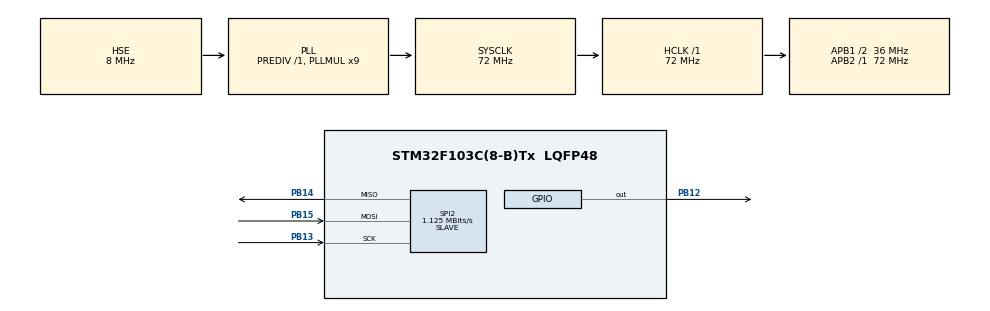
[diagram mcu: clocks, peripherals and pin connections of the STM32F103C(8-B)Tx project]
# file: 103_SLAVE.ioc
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Mcu.Family=STM32F1
Mcu.Name=STM32F103C(8-B)Tx
Mcu.Package=LQFP48
NVIC.PriorityGroup=NVIC_PRIORITYGROUP_4
NVIC.TIM4_IRQn=true\:15\:0\:false\:false\:true\:false\:true
NVIC.TimeBase=TIM4_IRQn
NVIC.TimeBaseIP=TIM4
PA13.Mode=Trace_Asynchronous_SW
PA13.Signal=SYS_JTMS-SWDIO
PA14.Mode=Trace_Asynchronous_SW
PA14.Signal=SYS_JTCK-SWCLK
PB12.GPIO_Speed=GPIO_SPEED_FREQ_HIGH
PB12.PinState=GPIO_PIN_SET
PB12.Signal=GPIO_Output
PB13.Mode=Full_Duplex_Slave
PB13.Signal=SPI2_SCK
PB14.Mode=Full_Duplex_Slave
PB14.Signal=SPI2_MISO
PB15.Mode=Full_Duplex_Slave
PB15.Signal=SPI2_MOSI
PB3.Mode=Trace_Asynchronous_SW
PB3.Signal=SYS_JTDO-TRACESWO
PD0-OSC_IN.Mode=HSE-External-Oscillator
PD0-OSC_IN.Signal=RCC_OSC_IN
PD1-OSC_OUT.Mode=HSE-External-Oscillator
PD1-OSC_OUT.Signal=RCC_OSC_OUT
ProjectManager.HeapSize=0x200
ProjectManager.StackSize=0x400
ProjectManager.TargetToolchain=STM32CubeIDE
RCC.AHBFreq_Value=72000000
RCC.APB1CLKDivider=RCC_HCLK_DIV2
RCC.APB1Freq_Value=36000000
RCC.APB1TimFreq_Value=72000000
RCC.APB2Freq_Value=72000000
RCC.APB2TimFreq_Value=72000000
RCC.HCLKFreq_Value=72000000
RCC.PLLMUL=RCC_PLL_MUL9
RCC.PLLSourceVirtual=RCC_PLLSOURCE_HSE
RCC.SYSCLKFreq_VALUE=72000000
RCC.SYSCLKSource=RCC_SYSCLKSOURCE_PLLCLK
RCC.USBFreq_Value=72000000
SPI2.BaudRatePrescaler=SPI_BAUDRATEPRESCALER_32
SPI2.CalculateBaudRate=1.125 MBits/s
SPI2.Direction=SPI_DIRECTION_2LINES
SPI2.Mode=SPI_MODE_SLAVE
SPI2.VirtualType=VM_SLAVE
VP_SYS_VS_tim4.Mode=TIM4
board=custom

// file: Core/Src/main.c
/* USER CODE BEGIN Header */
/**
  ******************************************************************************
  * @file           : main.c
  * @brief          : Main program body
  ******************************************************************************
  * @attention
  *
  * <h2><center>&copy; Copyright (c) 2021 STMicroelectronics.
  * All rights reserved.</center></h2>
  *
  * This software component is licensed by ST under BSD 3-Clause license,
  * the "License"; You may not use this file except in compliance with the
  * License. You may obtain a copy of the License at:
  *                        opensource.org/licenses/BSD-3-Clause
  *SLAVE
  ******************************************************************************
  */
/* USER CODE END Header */
#include "main.h"

/* USER CODE BEGIN Includes */
#include <stdio.h> /* для printf */
/* USER CODE END Includes */

SPI_HandleTypeDef hspi2;

void SystemClock_Config(void);
static void MX_GPIO_Init(void);
static void MX_SPI2_Init(void);

int main(void)
{

  /* MCU Configuration--------------------------------------------------------*/

  /* Reset of all peripherals, Initializes the Flash interface and the Systick. */
  HAL_Init();

  /* Configure the system clock */
  SystemClock_Config();

  /* Initialize all configured peripherals */
  MX_GPIO_Init();
  MX_SPI2_Init();
  /* USER CODE BEGIN 2 */
  //uint8_t TX_Data[10] = {10,11,12,13,14,15,16,17,18,19};
  uint8_t TX_Data[] = "Hi from SLAVE!";
  uint8_t RX_Data[18] = {0};
  HAL_GPIO_WritePin(GPIOB, GPIO_PIN_12, GPIO_PIN_SET);
  /* USER CODE END 2 */

  /* Infinite loop */
  while (1)
  {
		HAL_GPIO_WritePin(GPIOB, GPIO_PIN_12, GPIO_PIN_RESET); // CS во время передачи пин должен быть LOW
		HAL_SPI_Receive(&hspi2, RX_Data, sizeof(RX_Data), 5000);
		HAL_GPIO_WritePin(GPIOB, GPIO_PIN_12, GPIO_PIN_SET); // CS по окончании передачи пин должен быть HIGH

		HAL_GPIO_WritePin(GPIOB, GPIO_PIN_12, GPIO_PIN_RESET); // CS во время передачи пин должен быть LOW
		HAL_SPI_Transmit(&hspi2, TX_Data, sizeof(TX_Data), 5000);
		while (hspi2.State == HAL_SPI_STATE_BUSY);  // Ждем пока закончитася передача.
		//while(HAL_SPI_GetState(&hspi2) != HAL_SPI_STATE_READY);// Ждем завершения передачи SPI, прежде чем начать следующую передачу
		HAL_GPIO_WritePin(GPIOB, GPIO_PIN_12, GPIO_PIN_SET); // CS по окончании передачи пин должен быть HIGH
		printf("\n Resive data is: %s\n", RX_Data);
  }
}

void SystemClock_Config(void)
{
  RCC_OscInitTypeDef RCC_OscInitStruct = {0};
  RCC_ClkInitTypeDef RCC_ClkInitStruct = {0};

  /** Initializes the RCC Oscillators according to the specified parameters
  * in the RCC_OscInitTypeDef structure.
  */
  RCC_OscInitStruct.OscillatorType = RCC_OSCILLATORTYPE_HSE;
  RCC_OscInitStruct.HSEState = RCC_HSE_ON;
  RCC_OscInitStruct.HSEPredivValue = RCC_HSE_PREDIV_DIV1;
  RCC_OscInitStruct.HSIState = RCC_HSI_ON;
  RCC_OscInitStruct.PLL.PLLState = RCC_PLL_ON;
  RCC_OscInitStruct.PLL.PLLSource = RCC_PLLSOURCE_HSE;
  RCC_OscInitStruct.PLL.PLLMUL = RCC_PLL_MUL9;
  if (HAL_RCC_OscConfig(&RCC_OscInitStruct) != HAL_OK)
  {
    Error_Handler();
  }
  /** Initializes the CPU, AHB and APB buses clocks
  */
  RCC_ClkInitStruct.ClockType = RCC_CLOCKTYPE_HCLK|RCC_CLOCKTYPE_SYSCLK
                              |RCC_CLOCKTYPE_PCLK1|RCC_CLOCKTYPE_PCLK2;
  RCC_ClkInitStruct.SYSCLKSource = RCC_SYSCLKSOURCE_PLLCLK;
  RCC_ClkInitStruct.AHBCLKDivider = RCC_SYSCLK_DIV1;
  RCC_ClkInitStruct.APB1CLKDivider = RCC_HCLK_DIV2;
  RCC_ClkInitStruct.APB2CLKDivider = RCC_HCLK_DIV1;

  if (HAL_RCC_ClockConfig(&RCC_ClkInitStruct, FLASH_LATENCY_2) != HAL_OK)
  {
    Error_Handler();
  }
}

static void MX_SPI2_Init(void)
{

  /* SPI2 parameter configuration*/
  hspi2.Instance = SPI2;
  hspi2.Init.Mode = SPI_MODE_SLAVE;
  hspi2.Init.Direction = SPI_DIRECTION_2LINES;
  hspi2.Init.DataSize = SPI_DATASIZE_8BIT;
  hspi2.Init.CLKPolarity = SPI_POLARITY_LOW;
  hspi2.Init.CLKPhase = SPI_PHASE_1EDGE;
  hspi2.Init.NSS = SPI_NSS_SOFT;
  hspi2.Init.BaudRatePrescaler = SPI_BAUDRATEPRESCALER_32;
  hspi2.Init.FirstBit = SPI_FIRSTBIT_MSB;
  hspi2.Init.TIMode = SPI_TIMODE_DISABLE;
  hspi2.Init.CRCCalculation = SPI_CRCCALCULATION_DISABLE;
  hspi2.Init.CRCPolynomial = 10;
  if (HAL_SPI_Init(&hspi2) != HAL_OK)
  {
    Error_Handler();
  }

}

static void MX_GPIO_Init(void)
{
  GPIO_InitTypeDef GPIO_InitStruct = {0};

  /* GPIO Ports Clock Enable */
  __HAL_RCC_GPIOD_CLK_ENABLE();
  __HAL_RCC_GPIOB_CLK_ENABLE();
  __HAL_RCC_GPIOA_CLK_ENABLE();

  /*Configure GPIO pin Output Level */
  HAL_GPIO_WritePin(GPIOB, GPIO_PIN_12, GPIO_PIN_SET);

  /*Configure GPIO pin : PB12 */
  GPIO_InitStruct.Pin = GPIO_PIN_12;
  GPIO_InitStruct.Mode = GPIO_MODE_OUTPUT_PP;
  GPIO_InitStruct.Pull = GPIO_NOPULL;
  GPIO_InitStruct.Speed = GPIO_SPEED_FREQ_HIGH;
  HAL_GPIO_Init(GPIOB, &GPIO_InitStruct);

}

void HAL_TIM_PeriodElapsedCallback(TIM_HandleTypeDef *htim)
{
  if (htim->Instance == TIM4) {
    HAL_IncTick();
  }
}

void Error_Handler(void)
{
  __disable_irq();
  while (1)
  {
  }
}

/************************ (C) COPYRIGHT STMicroelectronics *****END OF FILE****/
